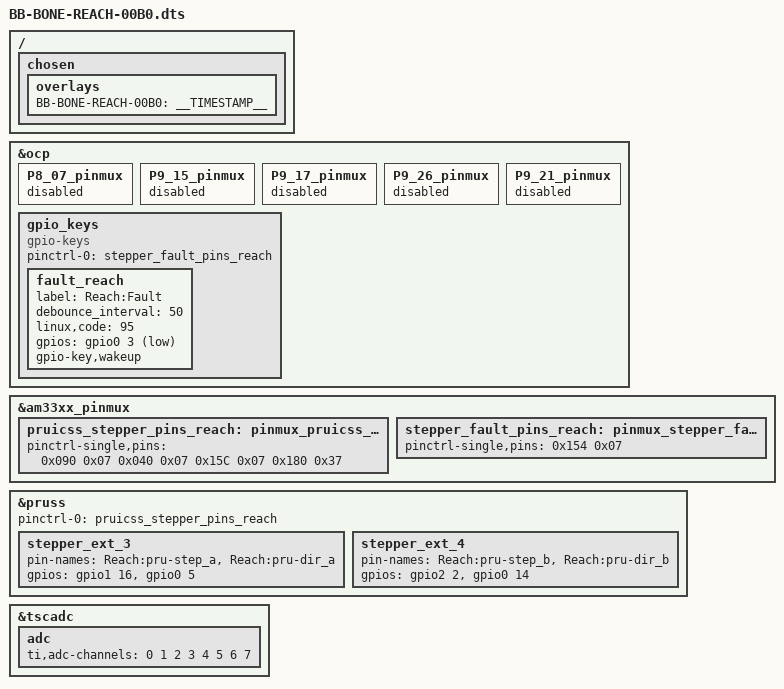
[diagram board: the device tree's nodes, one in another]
/*
 * Copyright (C) 2013 Intelligent Agent AS	<elias@iagent.no>
 *
 * This program is free software; you can redistribute it and/or modify
 * it under the terms of the GNU General Public License version 2 as
 * published by the Free Software Foundation.
 */

/dts-v1/;
/plugin/;

/ {
	/*
	 * Helper to show loaded overlays under: /proc/device-tree/chosen/overlays/
	 */
	fragment@0 {
		target-path="/";
		__overlay__ {

			chosen {
				overlays {
					BB-BONE-REACH-00B0 = __TIMESTAMP__;
				};
			};
		};
	};

	/*
	 * Free up the pins used by the cape from the pinmux helpers.
	 */
	fragment@1 {
		target = <&ocp>;
		__overlay__ {
			P8_07_pinmux { status = "disabled"; };
			P9_15_pinmux { status = "disabled"; };
			P9_17_pinmux { status = "disabled"; };
			P9_26_pinmux { status = "disabled"; };
			P9_21_pinmux { status = "disabled"; };
		};
	};

	fragment@2 {
		target = <&am33xx_pinmux>;
		__overlay__ {
			pruicss_stepper_pins_reach: pinmux_pruicss_stepper_pins_reach{
				pinctrl-single,pins = <
					0x090 0x07	/* P8_07: () = STEP_B = GPIO2_2 */
					0x040 0x07	/* P9_15: () = STEP_A = GPIO1_16 */
					0x15C 0x07	/* P9_17: () = DIR_A  = GPIO0_5 */
					0x180 0x37	/* P9_26: () = DIR_B  = GPIO0_14 */
				>;
			};

			stepper_fault_pins_reach: pinmux_stepper_fault_pins_reach {
				pinctrl-single,pins = <
					0x154 0x07	/* P9_21: () = FAULT_REACH = GPIO0_3 */
				>;
			};
		};
	};

	fragment@3 {
		target = <&pruss>;
		__overlay__{
			status = "okay";
			pinctrl-names = "default";
			pinctrl-0 = <&pruicss_stepper_pins_reach>;

			stepper_ext_3 {
				pin-names	= "Reach:pru-step_a", "Reach:pru-dir_a";
				gpios		= <&gpio1 16 0
						   &gpio0 5 0>;
			};

			stepper_ext_4 {
				pin-names	= "Reach:pru-step_b", "Reach:pru-dir_b";
				gpios		= <&gpio2 2 0
						   &gpio0 14 0>;
			};
		};
	};

	fragment@4 {
		target = <&ocp>;
		__overlay__ {

			gpio_keys {
			compatible = "gpio-keys";
			pinctrl-names = "default";
			pinctrl-0 = <&stepper_fault_pins_reach>;

			fault_reach {
				label               = "Reach:Fault";
				debounce_interval   = <50>;
				linux,code          = <95>;
				gpios               = <&gpio0 3 0x5>;
				gpio-key,wakeup;
				};
			};
		};
	};

	fragment@5 {
		target = <&tscadc>;
		__overlay__ {
			status = "okay";
			adc {
				ti,adc-channels = <0 1 2 3 4 5 6 7>;
			};
		};
	};
};
